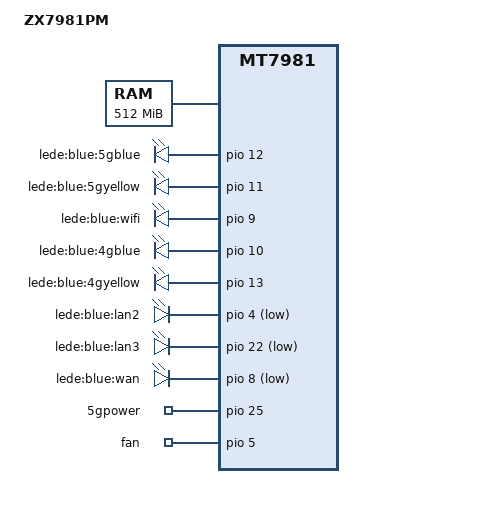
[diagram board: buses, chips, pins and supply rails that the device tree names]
/dts-v1/;
#include "mt7981.dtsi"

#include <dt-bindings/input/input.h>

/ {
	model = "ZX7981PM";
	compatible = "ZX7981PM";
	chosen {
		bootargs = "console=ttyS0,115200n1 loglevel=8  \
			earlycon=uart8250,mmio32,0x11002000";
	};

	memory {
		// fpga ddr2: 128MB*2
		reg = <0 0x40000000 0 0x20000000>;
	};

	gpio-leds {
		compatible = "gpio-leds";

		5gblue {
			label = "lede:blue:5gblue";
			gpios = <&pio 12 0>;
			linux,default-trigger = "none";
			default-state = "off";
		};

		5gyellow {
			label = "lede:blue:5gyellow";
			gpios = <&pio 11 0>;
			linux,default-trigger = "none";
			default-state = "off";
		};

		wifi {
			label = "lede:blue:wifi";
			gpios = <&pio 9 0>;
			linux,default-trigger = "none";
			default-state = "off";
		};

		4gblue {
			label = "lede:blue:4gblue";
			gpios = <&pio 10 0>;
			linux,default-trigger = "none";
			default-state = "off";
		};

		4gyellow {
			label = "lede:blue:4gyellow";
			gpios = <&pio 13 0>;
			linux,default-trigger = "none";
			default-state = "off";
		};

		lan2 {
			label = "lede:blue:lan2";
			gpios = <&pio 4 1>;
			linux,default-trigger = "none";
			default-state = "off";
		};

		lan3 {
			label = "lede:blue:lan3";
			gpios = <&pio 22 1>;
			linux,default-trigger = "none";
			default-state = "off";
		};

		wan {
			label = "lede:blue:wan";
			gpios = <&pio 8 1>;
			linux,default-trigger = "none";
			default-state = "off";
		};
	};

	gpio-export {
		compatible = "gpio-export";
		5gpower {
			gpio-export,name = "5gpower";
			gpio-export,output = <0>;
			gpios = <&pio 25 0>;
		};

		fan {
			gpio-export,name = "fan";
			gpio-export,output = <1>;
			gpios = <&pio 5 0>;
		};
	};
};
